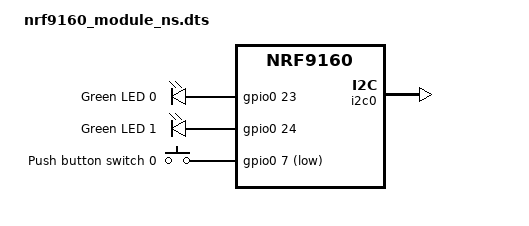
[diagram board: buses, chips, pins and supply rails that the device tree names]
/dts-v1/;
#include <nordic/nrf9160ns_sica.dtsi>
#include "nrf9160_module-pinctrl.dtsi"
#include "nrf9160_module-partitioning.dtsi"

/ {
	chosen {
		zephyr,flash = &flash0;
		zephyr,sram = &sram0_ns;
		zephyr,code-partition = &slot0_ns_partition;
	};

	leds   {
		compatible = "gpio-leds";
		led0: led_0 {
			gpios = <&gpio0 23 GPIO_ACTIVE_HIGH>;
			label = "Green LED 0";
		};
		led1: led_1 {
			gpios = <&gpio0 24 GPIO_ACTIVE_HIGH>;
			label = "Green LED 1";
		};
	};
	buttons {
		compatible = "gpio-keys";
		INTN: INTN {
			gpios = <&gpio0 7 (GPIO_ACTIVE_LOW)>;
			label = "Push button switch 0";
			zephyr,code = <INPUT_KEY_0>;
		};
	};

	aliases {
		led0 = &led0;
		led1 = &led1;
		intn = &INTN;
	};
};

&gpiote {
	status = "okay";
};

&gpio0 {
	status = "okay";
};

&i2c0 {
	compatible = "nordic,nrf-twim";
	status = "okay";
	pinctrl-0 = <&i2c0_default>;
	pinctrl-1 = <&i2c0_sleep>;
	pinctrl-names = "default", "sleep";
}; 
&power {
	status = "okay";
};
